# HDSC_HC32F460PETB register map
Vendor: HDSC; Series: ARMCM4; File version: 1.0
CPU: CM4 r0p1, little endian, MPU, FPU, 4 interrupt priority bits
Registers are 32-bit, read-write, reset 0x0 unless marked. A register's access mark holds for its fields unless they carry their own. Offsets are from the block's base; [hi:lo] are bit positions; {n}, {i} and the like mark numbered series.

## USBFS
Base 0x400C0000
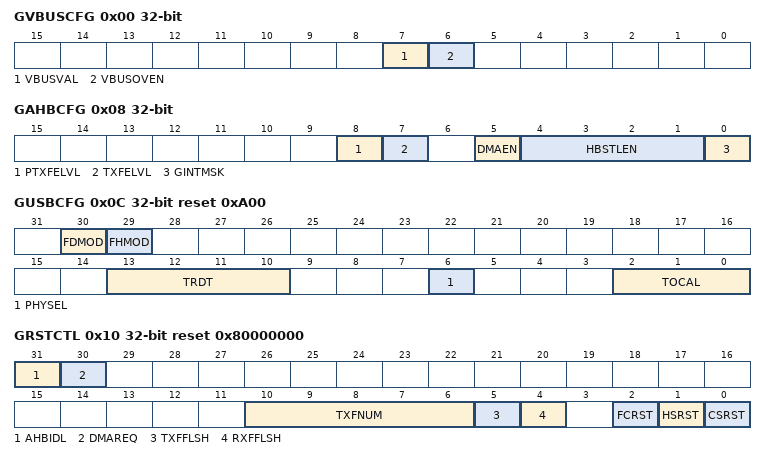
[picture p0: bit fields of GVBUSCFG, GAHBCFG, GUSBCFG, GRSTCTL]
0x00 GVBUSCFG
  [7] VBUSVAL, [6] VBUSOVEN
0x08 GAHBCFG
  [8] PTXFELVL, [7] TXFELVL, [5] DMAEN, [4:1] HBSTLEN, [0] GINTMSK
0x0C GUSBCFG reset 0xA00
  [30] FDMOD, [29] FHMOD, [13:10] TRDT, [6] PHYSEL, [2:0] TOCAL
0x10 GRSTCTL reset 0x80000000
  [31] AHBIDL ro, [30] DMAREQ ro, [10:6] TXFNUM, [5] TXFFLSH, [4] RXFFLSH, [2] FCRST, [1] HSRST, [0] CSRST
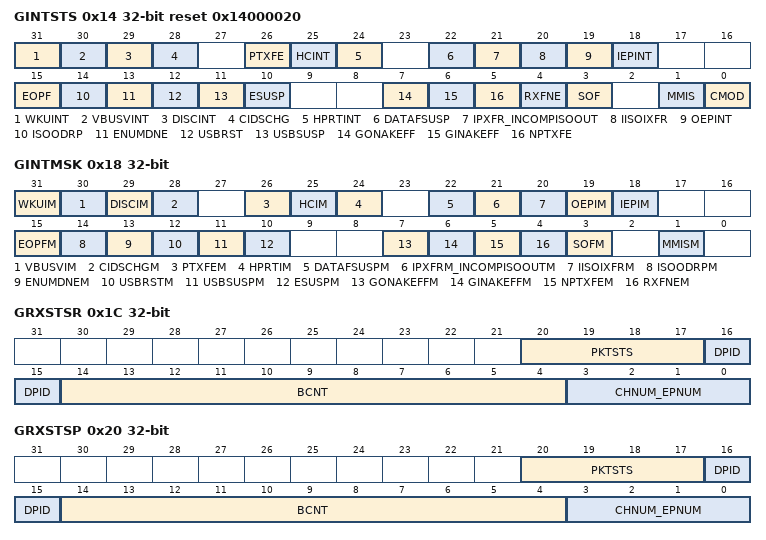
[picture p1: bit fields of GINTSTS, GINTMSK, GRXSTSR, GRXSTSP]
0x14 GINTSTS ro reset 0x14000020
  [31] WKUINT rw, [30] VBUSVINT rw, [29] DISCINT rw, [28] CIDSCHG rw, [26] PTXFE, [25] HCINT, [24] HPRTINT, [22] DATAFSUSP rw, [21] IPXFR_INCOMPISOOUT rw, [20] IISOIXFR rw, [19] OEPINT, [18] IEPINT, [15] EOPF rw, [14] ISOODRP rw, [13] ENUMDNE rw, [12] USBRST rw, [11] USBSUSP rw, [10] ESUSP rw, [7] GONAKEFF, [6] GINAKEFF, [5] NPTXFE, [4] RXFNE, [3] SOF rw, [1] MMIS rw, [0] CMOD
0x18 GINTMSK
  [31] WKUIM, [30] VBUSVIM, [29] DISCIM, [28] CIDSCHGM, [26] PTXFEM, [25] HCIM, [24] HPRTIM, [22] DATAFSUSPM, [21] IPXFRM_INCOMPISOOUTM, [20] IISOIXFRM, [19] OEPIM, [18] IEPIM, [15] EOPFM, [14] ISOODRPM, [13] ENUMDNEM, [12] USBRSTM, [11] USBSUSPM, [10] ESUSPM, [7] GONAKEFFM, [6] GINAKEFFM, [5] NPTXFEM, [4] RXFNEM, [3] SOFM, [1] MMISM
0x1C GRXSTSR ro
  [20:17] PKTSTS, [16:15] DPID, [14:4] BCNT, [3:0] CHNUM_EPNUM
0x20 GRXSTSP ro
  [20:17] PKTSTS, [16:15] DPID, [14:4] BCNT, [3:0] CHNUM_EPNUM
0x24 GRXFSIZ reset 0x140
  [10:0] RXFD
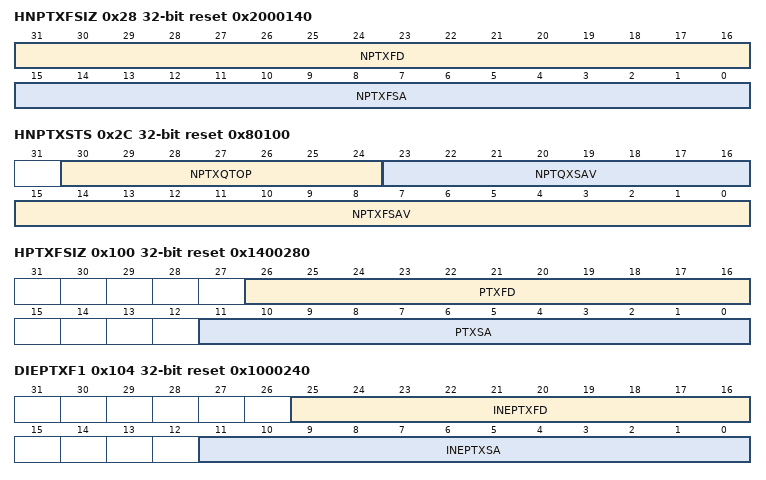
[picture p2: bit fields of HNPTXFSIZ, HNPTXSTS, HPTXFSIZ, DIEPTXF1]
0x28 HNPTXFSIZ reset 0x2000140
  [31:16] NPTXFD, [15:0] NPTXFSA
0x2C HNPTXSTS ro reset 0x80100
  [30:24] NPTXQTOP, [23:16] NPTQXSAV, [15:0] NPTXFSAV
0x3C CID reset 0x12345678
0x100 HPTXFSIZ reset 0x1400280
  [26:16] PTXFD, [11:0] PTXSA
0x104 DIEPTXF1 reset 0x1000240
  [25:16] INEPTXFD, [11:0] INEPTXSA
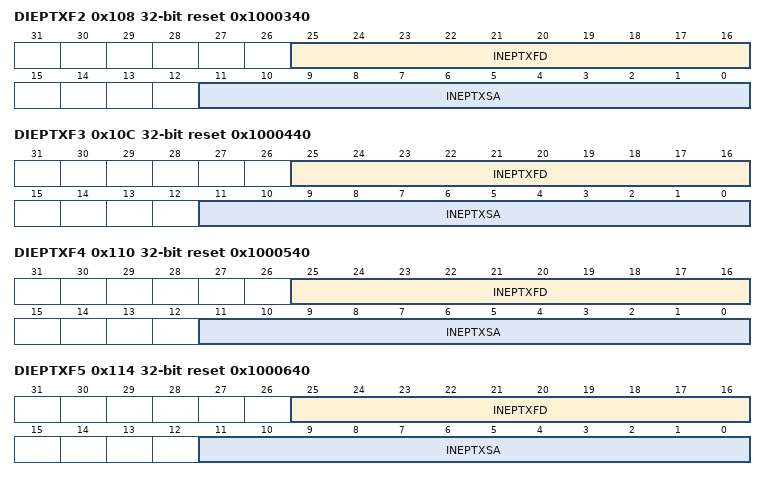
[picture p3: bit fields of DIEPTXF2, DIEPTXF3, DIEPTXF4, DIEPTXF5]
0x108 DIEPTXF2 reset 0x1000340
  [25:16] INEPTXFD, [11:0] INEPTXSA
0x10C DIEPTXF3 reset 0x1000440
  [25:16] INEPTXFD, [11:0] INEPTXSA
0x110 DIEPTXF4 reset 0x1000540
  [25:16] INEPTXFD, [11:0] INEPTXSA
0x114 DIEPTXF5 reset 0x1000640
  [25:16] INEPTXFD, [11:0] INEPTXSA
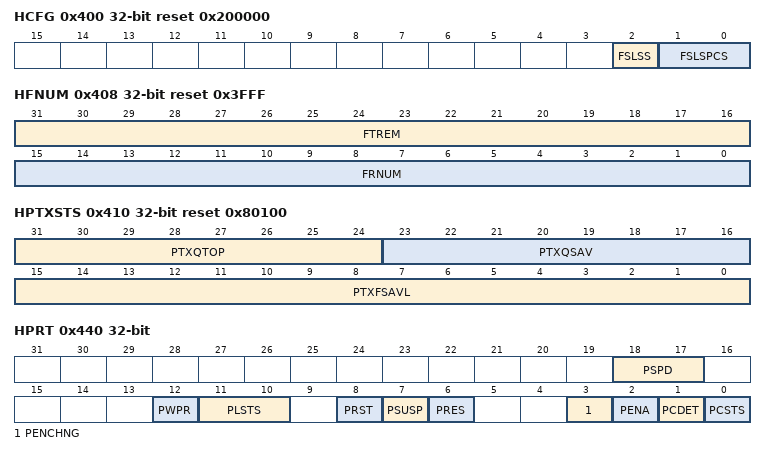
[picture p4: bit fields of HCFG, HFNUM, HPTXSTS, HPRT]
0x400 HCFG reset 0x200000
  [2] FSLSS, [1:0] FSLSPCS
0x404 HFIR reset 0xEA60
  [15:0] FRIVL
0x408 HFNUM ro reset 0x3FFF
  [31:16] FTREM, [15:0] FRNUM
0x410 HPTXSTS ro reset 0x80100
  [31:24] PTXQTOP, [23:16] PTXQSAV, [15:0] PTXFSAVL
0x414 HAINT ro
  [11:0] HAINT
0x418 HAINTMSK
  [11:0] HAINTM
0x440 HPRT ro
  [18:17] PSPD, [12] PWPR rw, [11:10] PLSTS, [8] PRST rw, [7] PSUSP rw, [6] PRES rw, [3] PENCHNG rw, [2] PENA rw, [1] PCDET rw, [0] PCSTS
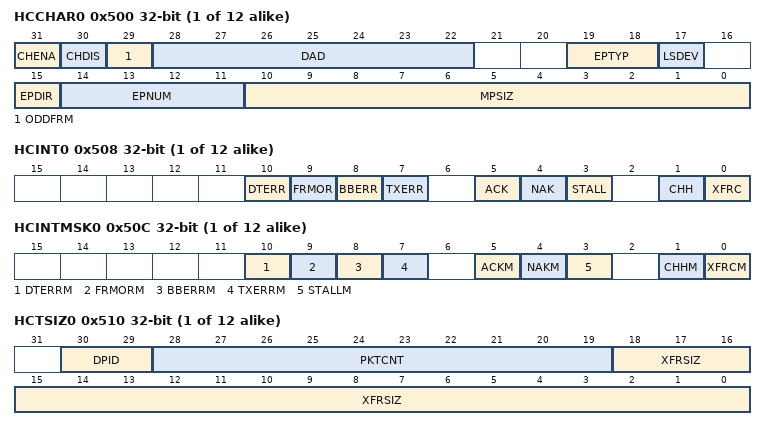
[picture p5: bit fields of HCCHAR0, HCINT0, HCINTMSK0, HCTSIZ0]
{0x500+0x20*i} HCCHAR{i} (i=0..11)
  [31] CHENA, [30] CHDIS, [29] ODDFRM, [28:22] DAD, [19:18] EPTYP ro, [17] LSDEV, [15] EPDIR, [14:11] EPNUM, [10:0] MPSIZ
{0x508+0x20*i} HCINT{i} (i=0..11)
  [10] DTERR, [9] FRMOR, [8] BBERR, [7] TXERR, [5] ACK, [4] NAK, [3] STALL, [1] CHH, [0] XFRC
{0x50C+0x20*i} HCINTMSK{i} (i=0..11)
  [10] DTERRM, [9] FRMORM, [8] BBERRM, [7] TXERRM, [5] ACKM, [4] NAKM, [3] STALLM, [1] CHHM, [0] XFRCM
{0x510+0x20*i} HCTSIZ{i} (i=0..11)
  [30:29] DPID, [28:19] PKTCNT, [18:0] XFRSIZ
{0x514+0x20*i} HCDMA{i} (i=0..11)
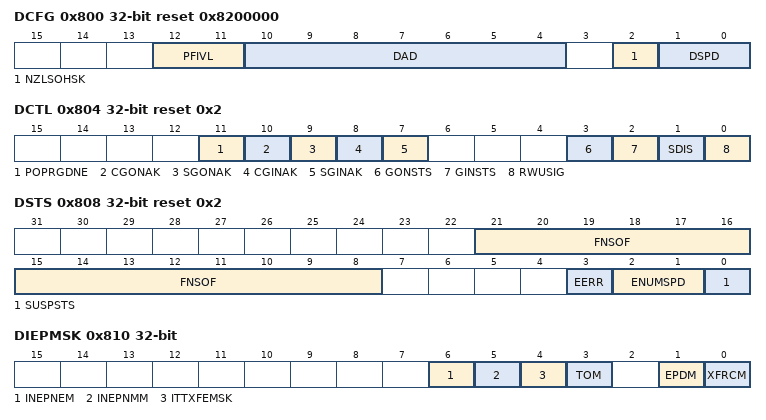
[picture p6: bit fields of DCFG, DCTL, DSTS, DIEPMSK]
0x800 DCFG reset 0x8200000
  [12:11] PFIVL, [10:4] DAD, [2] NZLSOHSK, [1:0] DSPD
0x804 DCTL reset 0x2
  [11] POPRGDNE, [10] CGONAK wo, [9] SGONAK wo, [8] CGINAK wo, [7] SGINAK wo, [3] GONSTS ro, [2] GINSTS ro, [1] SDIS, [0] RWUSIG
0x808 DSTS ro reset 0x2
  [21:8] FNSOF, [3] EERR, [2:1] ENUMSPD, [0] SUSPSTS
0x810 DIEPMSK
  [6] INEPNEM, [5] INEPNMM, [4] ITTXFEMSK, [3] TOM, [1] EPDM, [0] XFRCM
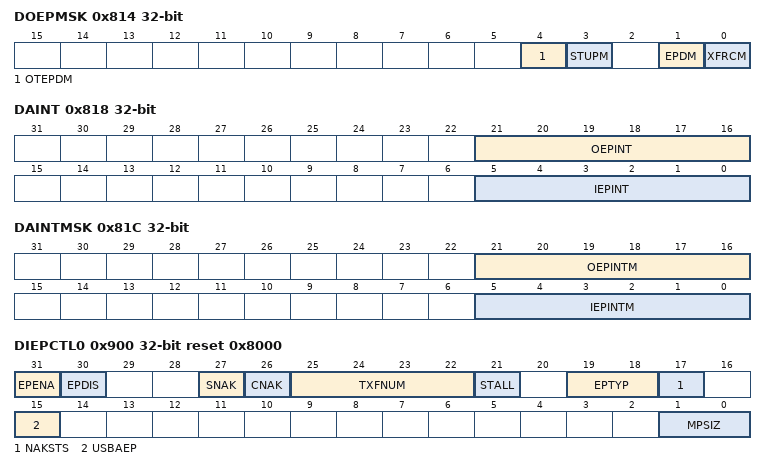
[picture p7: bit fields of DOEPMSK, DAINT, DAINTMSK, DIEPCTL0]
0x814 DOEPMSK
  [4] OTEPDM, [3] STUPM, [1] EPDM, [0] XFRCM
0x818 DAINT
  [21:16] OEPINT, [5:0] IEPINT
0x81C DAINTMSK
  [21:16] OEPINTM, [5:0] IEPINTM
0x834 DIEPEMPMSK
  [5:0] INEPTXFEM
0x900 DIEPCTL0 reset 0x8000
  [31] EPENA, [30] EPDIS, [27] SNAK, [26] CNAK, [25:22] TXFNUM, [21] STALL, [19:18] EPTYP ro, [17] NAKSTS ro, [15] USBAEP ro, [1:0] MPSIZ
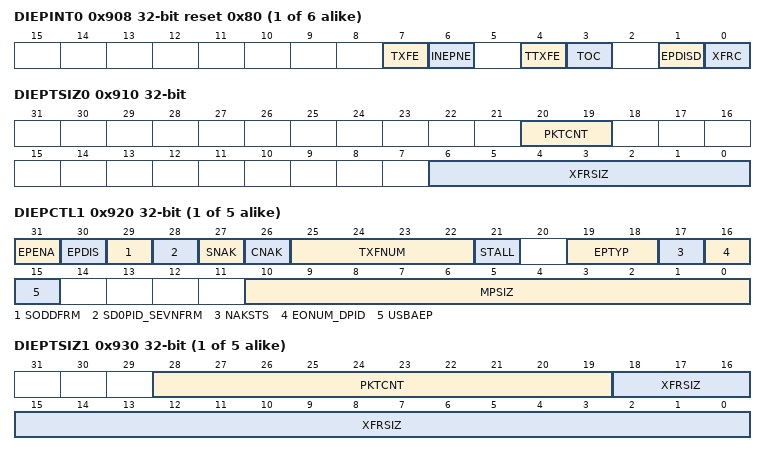
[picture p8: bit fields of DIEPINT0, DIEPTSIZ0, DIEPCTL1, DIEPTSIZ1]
{0x908+0x20*i} DIEPINT{i} reset 0x80 (i=0..5)
  [7] TXFE ro, [6] INEPNE, [4] TTXFE, [3] TOC, [1] EPDISD, [0] XFRC
0x910 DIEPTSIZ0
  [20:19] PKTCNT, [6:0] XFRSIZ
{0x914+0x20*i} DIEPDMA{i} (i=0..5)
{0x918+0x20*i} DTXFSTS{i} ro reset 0x100 (i=0..5)
  [15:0] INEPTFSAV
{0x900+0x20*i} DIEPCTL{i} (i=1..5)
  [31] EPENA, [30] EPDIS, [29] SODDFRM, [28] SD0PID_SEVNFRM, [27] SNAK, [26] CNAK, [25:22] TXFNUM, [21] STALL, [19:18] EPTYP ro, [17] NAKSTS ro, [16] EONUM_DPID ro, [15] USBAEP, [10:0] MPSIZ
{0x910+0x20*i} DIEPTSIZ{i} (i=1..5)
  [28:19] PKTCNT, [18:0] XFRSIZ
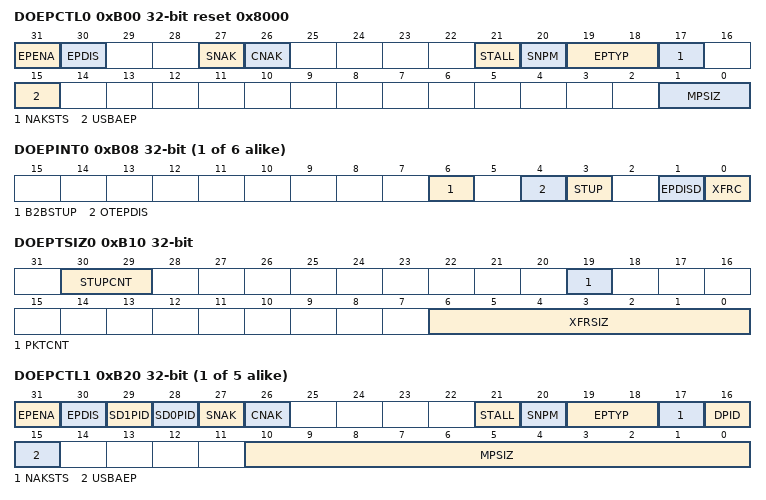
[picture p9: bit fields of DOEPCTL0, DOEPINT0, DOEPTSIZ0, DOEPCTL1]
0xB00 DOEPCTL0 reset 0x8000
  [31] EPENA, [30] EPDIS, [27] SNAK, [26] CNAK, [21] STALL, [20] SNPM, [19:18] EPTYP, [17] NAKSTS ro, [15] USBAEP ro, [1:0] MPSIZ
{0xB08+0x20*i} DOEPINT{i} (i=0..5)
  [6] B2BSTUP, [4] OTEPDIS, [3] STUP, [1] EPDISD, [0] XFRC
0xB10 DOEPTSIZ0
  [30:29] STUPCNT, [19] PKTCNT, [6:0] XFRSIZ
{0xB14+0x20*i} DOEPDMA{i} (i=0..5)
{0xB00+0x20*i} DOEPCTL{i} (i=1..5)
  [31] EPENA, [30] EPDIS, [29] SD1PID, [28] SD0PID, [27] SNAK, [26] CNAK, [21] STALL, [20] SNPM, [19:18] EPTYP, [17] NAKSTS ro, [16] DPID ro, [15] USBAEP ro, [10:0] MPSIZ
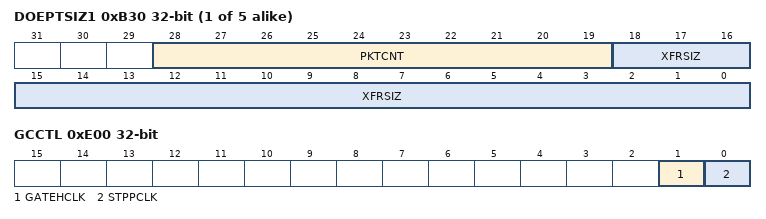
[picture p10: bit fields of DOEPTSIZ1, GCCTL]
{0xB10+0x20*i} DOEPTSIZ{i} (i=1..5)
  [28:19] PKTCNT, [18:0] XFRSIZ
0xE00 GCCTL
  [1] GATEHCLK, [0] STPPCLK
